# VPAC0_DRU_UTC_VPAC0_DRU_MMR_CFG_DRU_DRU_QUEUE register map
Vendor: Texas Instruments
Peripheral module from a debugger description file (folder J7ES).
Registers are 64-bit, access per field, reset 0x0 unless marked. A register's access mark holds for its fields unless they carry their own. Offsets are as the file gives them; lines under a group give offsets from that group; [hi:lo] are bit positions; {n}, {i} and the like mark numbered series; 'fields as' and 'values as' point back to an identical list; <NAME> marks a mode.

## VPAC0_DRU_UTC_VPAC0_DRU_MMR_CFG_DRU_DRU_QUEUE
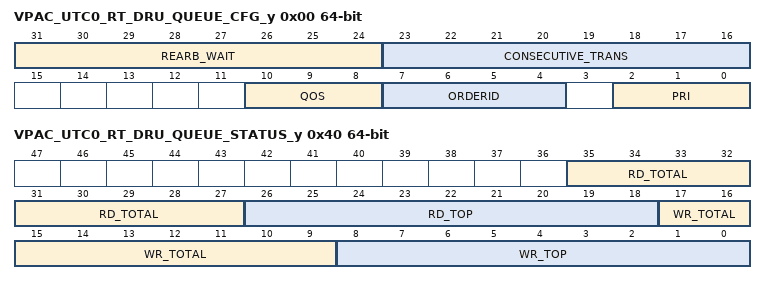
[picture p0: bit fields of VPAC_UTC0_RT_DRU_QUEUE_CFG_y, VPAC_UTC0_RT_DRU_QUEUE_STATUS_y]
0x00 VPAC_UTC0_RT_DRU_QUEUE_CFG_y — Configuration Register for Queue 0 Offset = 00208000h + (y * 8h); where y = 0h to 4h
  [31:24] REARB_WAIT rw — This is the number of commands that will be sent by other queues before allowing the queue to arbitrate again for the right to send commands.
  [23:16] CONSECUTIVE_TRANS rw — This is the number of consecutive transactions that will be sent before allowing another queue of equal level to arbitrate to send commands.
  [10:8] QOS rw — This configures the QOS for QUEUE0.
  [7:4] ORDERID rw — This configures the orderid for QUEUE0.
  [2:0] PRI rw — This configures the priority for QUEUE0.
0x40 VPAC_UTC0_RT_DRU_QUEUE_STATUS_y ro — Status Register for Queue 0 Offset = 00208040h + (y * 8h); where y = 0h to 4h
  [35:27] RD_TOTAL — This is the channel that the read half is currently working on.
  [26:18] RD_TOP — This is the channel that the read half is currently working on.
  [17:9] WR_TOTAL — This is the channel that the read half is currently working on.
  [8:0] WR_TOP — This is the channel that the write half is currently working on.
